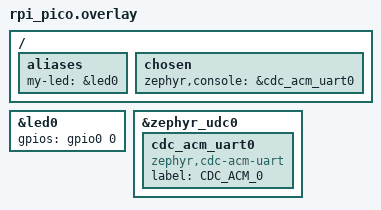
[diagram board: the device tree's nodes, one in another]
/ {
    aliases{
        my-led = &led0;
    };

    chosen{
        zephyr,console = &cdc_acm_uart0;
    };
};

&led0 {
    gpios = <&gpio0 0 GPIO_ACTIVE_HIGH>;
};

&zephyr_udc0 {
    cdc_acm_uart0: cdc_acm_uart0 {
        compatible = "zephyr,cdc-acm-uart";
        label = "CDC_ACM_0";
    };
};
